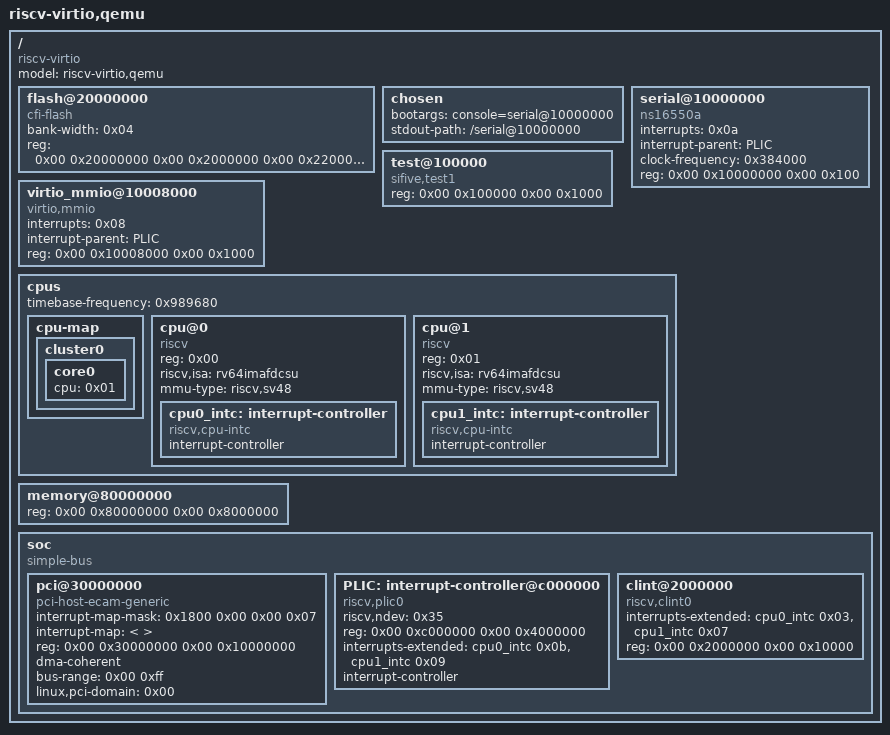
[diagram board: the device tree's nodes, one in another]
// virt.dts

/dts-v1/;

 / {
    #address-cells = <0x02>;
    #size-cells = <0x02>;
    compatible = "riscv-virtio";
    model = "riscv-virtio,qemu";

    flash@20000000 {
        bank-width = <0x04>;
        reg = <0x00 0x20000000 0x00 0x2000000 0x00 0x22000000 0x00 0x2000000>;
        compatible = "cfi-flash";
        status = "okay";
    };

    chosen {
        // Configuración de argumentos de arranque para xv6
        bootargs = "console=serial@10000000";
        stdout-path = "/serial@10000000";
    };

    // Nodo UART renombrado a serial@10000000 para compatibilidad con el parser
    serial@10000000 {
        interrupts = <0x0a>;
        interrupt-parent = <&PLIC>;
        clock-frequency = <0x384000>;
        reg = <0x00 0x10000000 0x00 0x100>;
        compatible = "ns16550a";
        status = "okay";
    };

    test@100000 {
        reg = <0x00 0x100000 0x00 0x1000>;
        compatible = "sifive,test1\0sifive,test0";
        status = "okay";
    };

    virtio_mmio@10008000 {
        interrupts = <0x08>;
        interrupt-parent = <&PLIC>;
        reg = <0x00 0x10008000 0x00 0x1000>;
        compatible = "virtio,mmio";
        status = "okay";
    };
    
    // ... otros dispositivos virtio_mmio omitidos por brevedad ...

    cpus {
        #address-cells = <0x01>;
        #size-cells = <0x00>;
        timebase-frequency = <0x989680>;

        cpu-map {

            cluster0 {

                core0 {
                    cpu = <0x01>;
                };
            };
        };

        cpu@0 {
            phandle = <0x01>;
            device_type = "cpu";
            reg = <0x00>;
            status = "okay";
            compatible = "riscv";
            riscv,isa = "rv64imafdcsu";
            mmu-type = "riscv,sv48";

            cpu0_intc: interrupt-controller {
                #interrupt-cells = <0x01>;
                interrupt-controller;
                compatible = "riscv,cpu-intc";
                phandle = <0x02>;
                #address-cells = <0x00>;
                #size-cells = <0x00>;
            };
        };

        cpu@1 {
            phandle = <0x04>;
            device_type = "cpu";
            reg = <0x01>;
            status = "okay";
            compatible = "riscv";
            riscv,isa = "rv64imafdcsu";
            mmu-type = "riscv,sv48";

            cpu1_intc: interrupt-controller {
                #interrupt-cells = <0x01>;
                interrupt-controller;
                compatible = "riscv,cpu-intc";
                phandle = <0x05>;
                #address-cells = <0x00>;
                #size-cells = <0x00>;
            };
        };
    };

    memory@80000000 {
        device_type = "memory";
        reg = <0x00 0x80000000 0x00 0x8000000>; // 128 MB de RAM
        status = "okay";
    };

    soc {
        #address-cells = <0x02>;
        #size-cells = <0x02>;
        compatible = "simple-bus";
        ranges;

        pci@30000000 {
            interrupt-map-mask = <0x1800 0x00 0x00 0x07>;
            interrupt-map = <
                // Definición de mapeo de interrupciones
                // ... contenido omitido por brevedad ...
            >;
            ranges = <
                0x1000000 0x00 0x00 0x00 0x3000000 0x00 0x10000
                0x2000000 0x00 0x40000000 0x00 0x40000000 0x00 0x40000
            >;
            reg = <0x00 0x30000000 0x00 0x10000000>;
            dma-coherent;
            bus-range = <0x00 0xff>;
            linux,pci-domain = <0x00>;
            device_type = "pci";
            compatible = "pci-host-ecam-generic";
            #size-cells = <0x02>;
            #interrupt-cells = <0x01>;
            #address-cells = <0x03>;
            status = "okay";
        };

        // Asignación de etiqueta "PLIC" al controlador de interrupciones
        PLIC: interrupt-controller@c000000 {
            phandle = <0x03>;
            riscv,ndev = <0x35>;
            reg = <0x00 0xc000000 0x00 0x4000000>;
            interrupts-extended = <&cpu0_intc 0x0b &cpu1_intc 0x09>;
            interrupt-controller;
            compatible = "riscv,plic0";
            #interrupt-cells = <0x01>;
            #address-cells = <0x00>;
            status = "okay";
        };

        clint@2000000 {
            interrupts-extended = <&cpu0_intc 0x03 &cpu1_intc 0x07>;
            reg = <0x00 0x2000000 0x00 0x10000>;
            compatible = "riscv,clint0";
            status = "okay";
        };
    };
};

